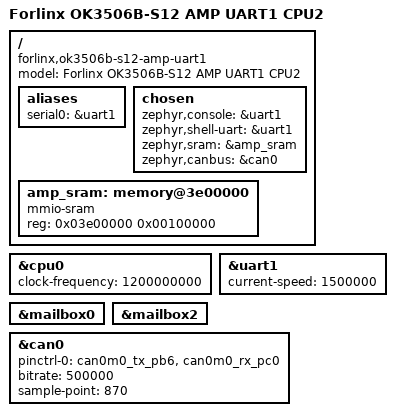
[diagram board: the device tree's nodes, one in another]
/*
 * SPDX-License-Identifier: Apache-2.0
 */

/dts-v1/;

#include <arm/rockchip/rk3506.dtsi>

/ {
	model = "Forlinx OK3506B-S12 AMP UART1 CPU2";
	compatible = "forlinx,ok3506b-s12-amp-uart1", "rockchip,rk3506-amp-uart1";

	aliases {
		serial0 = &uart1;
	};

	chosen {
		zephyr,console = &uart1;
		zephyr,shell-uart = &uart1;
		zephyr,sram = &amp_sram;
		zephyr,canbus = &can0;
	};

	amp_sram: memory@3e00000 {
		device_type = "memory";
		compatible = "mmio-sram";
		reg = <0x03e00000 0x00100000>;
	};
};

&cpu0 {
	clock-frequency = <1200000000>;
};

&uart1 {
	status = "okay";
	current-speed = <1500000>;
};

&mailbox0 {
	status = "okay";
};

&mailbox2 {
	status = "okay";
};

&can0 {
	status = "okay";
	pinctrl-0 = <&can0m0_tx_pb6 &can0m0_rx_pc0>;
	pinctrl-names = "default";
	bitrate = <500000>;
	sample-point = <870>;
};
